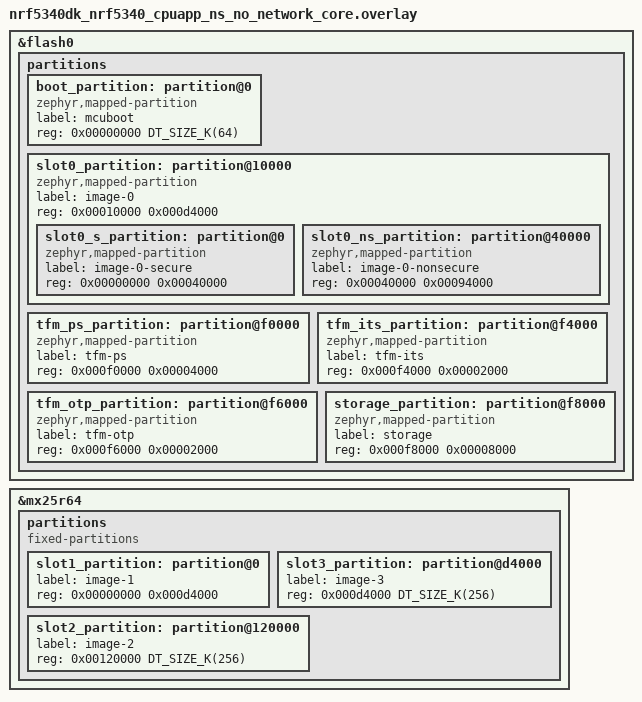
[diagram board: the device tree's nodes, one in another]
/*
 * Copyright (c) 2026 Nordic Semiconductor ASA
 *
 * SPDX-License-Identifier: LicenseRef-Nordic-5-Clause
 *
 * Non-secure (TF-M) memory map for QSPI XIP split image without network core.
 */

/delete-node/ &boot_partition;
/delete-node/ &slot0_partition;
/delete-node/ &slot1_partition;
/delete-node/ &storage_partition;

&flash0 {
	partitions {
		boot_partition: partition@0 {
			compatible = "zephyr,mapped-partition";
			label = "mcuboot";
			reg = <0x00000000 DT_SIZE_K(64)>;
		};

		slot0_partition: partition@10000 {
			compatible = "zephyr,mapped-partition";
			label = "image-0";
			reg = <0x00010000 0x000d4000>;
			ranges = <0x0 0x00010000 0x000d4000>;
			#address-cells = <1>;
			#size-cells = <1>;

			slot0_s_partition: partition@0 {
				compatible = "zephyr,mapped-partition";
				label = "image-0-secure";
				reg = <0x00000000 0x00040000>;
			};

			slot0_ns_partition: partition@40000 {
				compatible = "zephyr,mapped-partition";
				label = "image-0-nonsecure";
				reg = <0x00040000 0x00094000>;
			};
		};

		tfm_ps_partition: partition@f0000 {
			compatible = "zephyr,mapped-partition";
			label = "tfm-ps";
			reg = <0x000f0000 0x00004000>;
		};

		tfm_its_partition: partition@f4000 {
			compatible = "zephyr,mapped-partition";
			label = "tfm-its";
			reg = <0x000f4000 0x00002000>;
		};

		tfm_otp_partition: partition@f6000 {
			compatible = "zephyr,mapped-partition";
			label = "tfm-otp";
			reg = <0x000f6000 0x00002000>;
		};

		storage_partition: partition@f8000 {
			compatible = "zephyr,mapped-partition";
			label = "storage";
			reg = <0x000f8000 0x00008000>;
		};
	};
};

&mx25r64 {
	status = "okay";

	partitions {
		compatible = "fixed-partitions";
		#address-cells = <1>;
		#size-cells = <1>;

		slot1_partition: partition@0 {
			label = "image-1";
			reg = <0x00000000 0x000d4000>;
		};

		slot3_partition: partition@d4000 {
			label = "image-3";
			reg = <0x000d4000 DT_SIZE_K(256)>;
		};

		slot2_partition: partition@120000 {
			label = "image-2";
			reg = <0x00120000 DT_SIZE_K(256)>;
		};
	};
};
